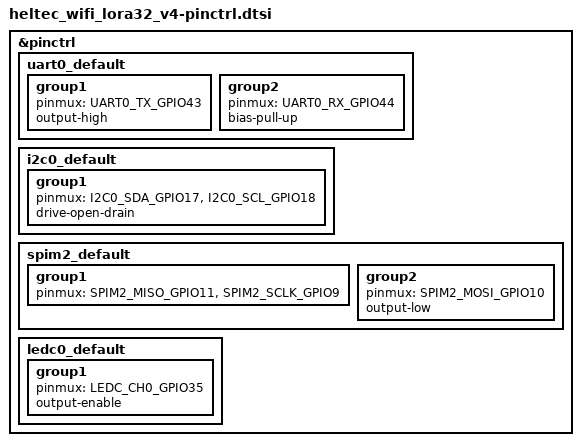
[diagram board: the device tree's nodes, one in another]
/*
 * SPDX-License-Identifier: Apache-2.0
 * Heltec WiFi LoRa 32 V4 — Pin Control Definitions
 *
 * Pin assignments (identical to V3):
 *   UART0:  TX=GPIO43, RX=GPIO44
 *   I2C0:   SDA=GPIO17, SCL=GPIO18   (SSD1306 OLED + sensors)
 *   SPI2:   SCLK=GPIO9, MOSI=GPIO10, MISO=GPIO11  (SX1262 LoRa)
 *   LEDC0:  CH0=GPIO35  (PWM LED)
 */

#include <zephyr/dt-bindings/pinctrl/esp-pinctrl-common.h>
#include <zephyr/dt-bindings/pinctrl/esp32s3-pinctrl.h>
#include <zephyr/dt-bindings/pinctrl/esp32s3-gpio-sigmap.h>

&pinctrl {
	uart0_default: uart0_default {
		group1 {
			pinmux = <UART0_TX_GPIO43>;
			output-high;
		};
		group2 {
			pinmux = <UART0_RX_GPIO44>;
			bias-pull-up;
		};
	};

	i2c0_default: i2c0_default {
		group1 {
			pinmux = <I2C0_SDA_GPIO17>,
				 <I2C0_SCL_GPIO18>;
			drive-open-drain;
		};
	};

	spim2_default: spim2_default {
		group1 {
			pinmux = <SPIM2_MISO_GPIO11>,
				 <SPIM2_SCLK_GPIO9>;
		};
		group2 {
			pinmux = <SPIM2_MOSI_GPIO10>;
			output-low;
		};
	};

	ledc0_default: ledc0_default {
		group1 {
			pinmux = <LEDC_CH0_GPIO35>;
			output-enable;
		};
	};
};
